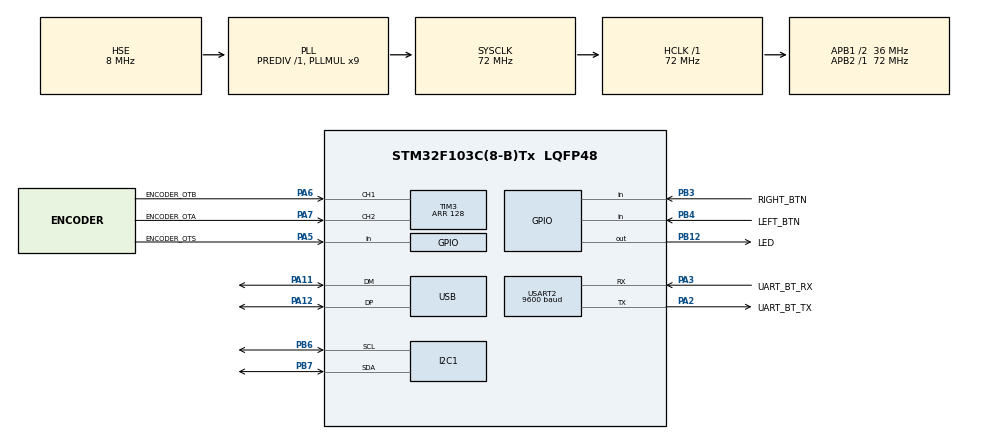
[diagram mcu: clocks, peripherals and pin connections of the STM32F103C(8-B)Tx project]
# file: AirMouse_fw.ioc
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Dma.Request0=USART2_RX
Dma.USART2_RX.0.Direction=DMA_PERIPH_TO_MEMORY
Dma.USART2_RX.0.Instance=DMA1_Channel6
Dma.USART2_RX.0.MemDataAlignment=DMA_MDATAALIGN_BYTE
Dma.USART2_RX.0.MemInc=DMA_MINC_ENABLE
Dma.USART2_RX.0.Mode=DMA_CIRCULAR
Dma.USART2_RX.0.PeriphDataAlignment=DMA_PDATAALIGN_BYTE
Dma.USART2_RX.0.PeriphInc=DMA_PINC_DISABLE
Dma.USART2_RX.0.Priority=DMA_PRIORITY_LOW
Mcu.Family=STM32F1
Mcu.Name=STM32F103C(8-B)Tx
Mcu.Package=LQFP48
NVIC.DMA1_Channel6_IRQn=true\:0\:0\:false\:false\:true\:false\:true\:true
NVIC.PriorityGroup=NVIC_PRIORITYGROUP_4
NVIC.TIM3_IRQn=true\:0\:0\:false\:false\:true\:true\:true\:true
NVIC.USART2_IRQn=true\:0\:0\:false\:false\:true\:true\:true\:true
NVIC.USB_LP_CAN1_RX0_IRQn=true\:0\:0\:false\:false\:true\:false\:true\:true
PA11.Mode=Device
PA11.Signal=USB_DM
PA12.Mode=Device
PA12.Signal=USB_DP
PA13.Mode=Serial_Wire
PA13.Signal=SYS_JTMS-SWDIO
PA14.Mode=Serial_Wire
PA14.Signal=SYS_JTCK-SWCLK
PA2.GPIO_Label=UART_BT_TX
PA2.Mode=Asynchronous
PA2.Signal=USART2_TX
PA3.GPIO_Label=UART_BT_RX
PA3.Mode=Asynchronous
PA3.Signal=USART2_RX
PA5.GPIO_Label=ENCODER_OTS
PA5.Signal=GPIO_Input
PA6.GPIO_Label=ENCODER_OTB
PA6.Signal=S_TIM3_CH1
PA7.GPIO_Label=ENCODER_OTA
PA7.Signal=S_TIM3_CH2
PB12.GPIO_Label=LED
PB12.Signal=GPIO_Output
PB3.GPIO_Label=RIGHT_BTN
PB3.GPIO_PuPd=GPIO_PULLDOWN
PB3.Signal=GPIO_Input
PB4.GPIO_Label=LEFT_BTN
PB4.GPIO_PuPd=GPIO_PULLDOWN
PB4.Signal=GPIO_Input
PB6.Mode=I2C
PB6.Signal=I2C1_SCL
PB7.Mode=I2C
PB7.Signal=I2C1_SDA
PD0-OSC_IN.Mode=HSE-External-Oscillator
PD0-OSC_IN.Signal=RCC_OSC_IN
PD1-OSC_OUT.Mode=HSE-External-Oscillator
PD1-OSC_OUT.Signal=RCC_OSC_OUT
ProjectManager.HeapSize=0x200
ProjectManager.StackSize=0x400
ProjectManager.TargetToolchain=CMake
RCC.ADCPresc=RCC_ADCPCLK2_DIV6
RCC.AHBFreq_Value=72000000
RCC.APB1CLKDivider=RCC_HCLK_DIV2
RCC.APB1Freq_Value=36000000
RCC.APB1TimFreq_Value=72000000
RCC.APB2Freq_Value=72000000
RCC.APB2TimFreq_Value=72000000
RCC.HCLKFreq_Value=72000000
RCC.PLLMUL=RCC_PLL_MUL9
RCC.PLLSourceVirtual=RCC_PLLSOURCE_HSE
RCC.SYSCLKFreq_VALUE=72000000
RCC.SYSCLKSource=RCC_SYSCLKSOURCE_PLLCLK
RCC.USBFreq_Value=48000000
RCC.USBPrescaler=RCC_USBCLKSOURCE_PLL_DIV1_5
SH.S_TIM3_CH1.0=TIM3_CH1,Encoder_Interface
SH.S_TIM3_CH2.0=TIM3_CH2,Encoder_Interface
TIM3.Period=128
USART2.BaudRate=9600
USART2.VirtualMode=VM_ASYNC
USB_DEVICE.CLASS_NAME_FS=CDC
USB_DEVICE.VirtualMode=Cdc
USB_DEVICE.VirtualModeFS=Cdc_FS
VP_CRC_VS_CRC.Mode=CRC_Activate
VP_USB_DEVICE_VS_USB_DEVICE_CDC_FS.Mode=CDC_FS
board=custom

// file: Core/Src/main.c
/* USER CODE BEGIN Header */
/**
 ******************************************************************************
 * @file           : main.c
 * @brief          : Main program body
 ******************************************************************************
 * @attention
 *
 * Copyright (c) 2024 STMicroelectronics.
 * All rights reserved.
 *
 * This software is licensed under terms that can be found in the LICENSE file
 * in the root directory of this software component.
 * If no LICENSE file comes with this software, it is provided AS-IS.
 *
 ******************************************************************************
 */
/* USER CODE END Header */
#include "main.h"
#include "crc.h"
#include "dma.h"
#include "i2c.h"
#include "tim.h"
#include "usart.h"
#include "usb_device.h"
#include "gpio.h"

/* USER CODE BEGIN Includes */
#include "mpu6050.h"
#include "button.h"
#include "bluetooth.h"
#include "data_processing.h"
#include "encoder.h"
/* USER CODE END Includes */

void SystemClock_Config(void);

int main(void)
{

  /* MCU Configuration--------------------------------------------------------*/

  /* Reset of all peripherals, Initializes the Flash interface and the Systick. */
  HAL_Init();

  /* Configure the system clock */
  SystemClock_Config();

  /* Initialize all configured peripherals */
  MX_GPIO_Init();
  MX_DMA_Init();
  MX_I2C1_Init();
  MX_USART2_UART_Init();
  MX_TIM3_Init();
  MX_USB_DEVICE_Init();
  MX_CRC_Init();
  /* USER CODE BEGIN 2 */
  MPU6050_Init(0x06);
  dataProcessingInit();
  buttonInit();
  encoderInit();
  /* USER CODE END 2 */

  /* Infinite loop */
  while (1)
  {

    /* USER CODE BEGIN 3 */
    readData();
    dataProcessing();
  }
  /* USER CODE END 3 */
}

void SystemClock_Config(void)
{
  RCC_OscInitTypeDef RCC_OscInitStruct = {0};
  RCC_ClkInitTypeDef RCC_ClkInitStruct = {0};
  RCC_PeriphCLKInitTypeDef PeriphClkInit = {0};

  /** Initializes the RCC Oscillators according to the specified parameters
  * in the RCC_OscInitTypeDef structure.
  */
  RCC_OscInitStruct.OscillatorType = RCC_OSCILLATORTYPE_HSE;
  RCC_OscInitStruct.HSEState = RCC_HSE_ON;
  RCC_OscInitStruct.HSEPredivValue = RCC_HSE_PREDIV_DIV1;
  RCC_OscInitStruct.HSIState = RCC_HSI_ON;
  RCC_OscInitStruct.PLL.PLLState = RCC_PLL_ON;
  RCC_OscInitStruct.PLL.PLLSource = RCC_PLLSOURCE_HSE;
  RCC_OscInitStruct.PLL.PLLMUL = RCC_PLL_MUL9;
  if (HAL_RCC_OscConfig(&RCC_OscInitStruct) != HAL_OK)
  {
    Error_Handler();
  }

  /** Initializes the CPU, AHB and APB buses clocks
  */
  RCC_ClkInitStruct.ClockType = RCC_CLOCKTYPE_HCLK|RCC_CLOCKTYPE_SYSCLK
                              |RCC_CLOCKTYPE_PCLK1|RCC_CLOCKTYPE_PCLK2;
  RCC_ClkInitStruct.SYSCLKSource = RCC_SYSCLKSOURCE_PLLCLK;
  RCC_ClkInitStruct.AHBCLKDivider = RCC_SYSCLK_DIV1;
  RCC_ClkInitStruct.APB1CLKDivider = RCC_HCLK_DIV2;
  RCC_ClkInitStruct.APB2CLKDivider = RCC_HCLK_DIV1;

  if (HAL_RCC_ClockConfig(&RCC_ClkInitStruct, FLASH_LATENCY_2) != HAL_OK)
  {
    Error_Handler();
  }
  PeriphClkInit.PeriphClockSelection = RCC_PERIPHCLK_USB;
  PeriphClkInit.UsbClockSelection = RCC_USBCLKSOURCE_PLL_DIV1_5;
  if (HAL_RCCEx_PeriphCLKConfig(&PeriphClkInit) != HAL_OK)
  {
    Error_Handler();
  }
}

void Error_Handler(void)
{
  __disable_irq();
  while (1)
  {
  }
}
